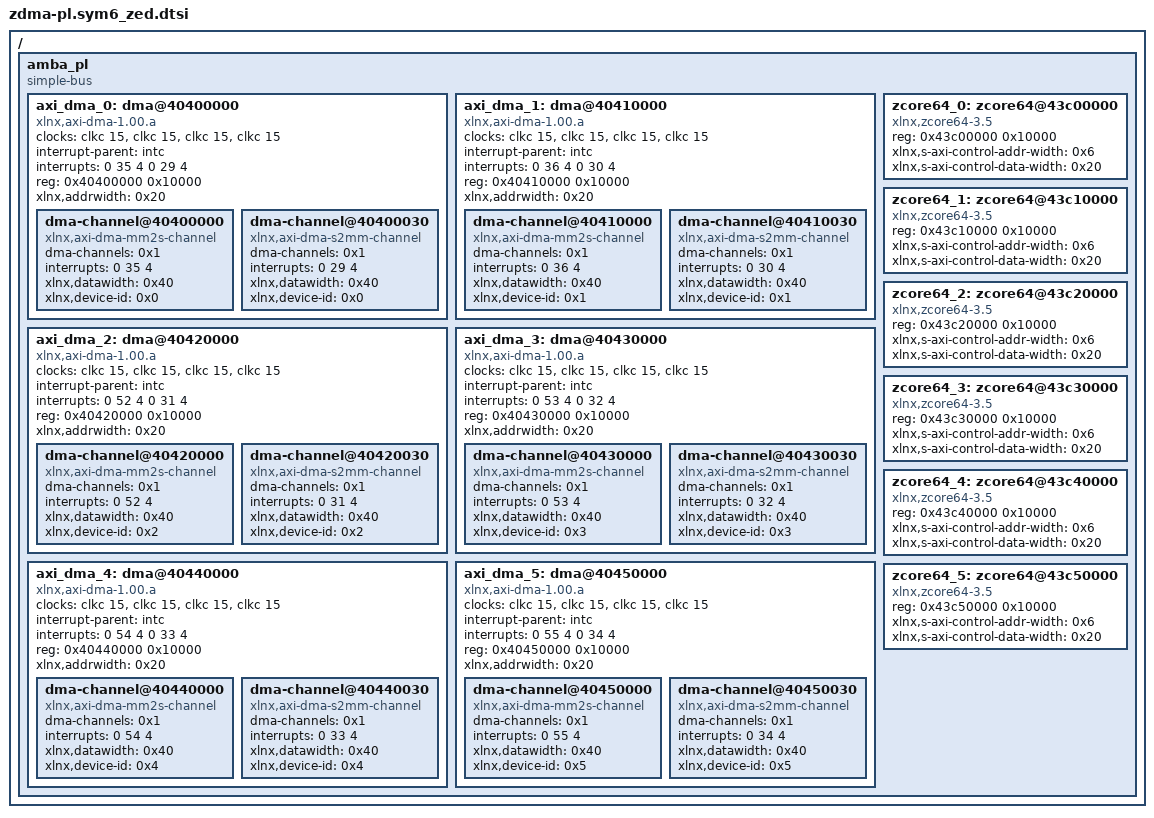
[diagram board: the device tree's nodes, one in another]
/*
 * CAUTION: This file is automatically generated by Xilinx.
 * Version: HSI 2017.2
 * Today is: Tue Jan 16 02:38:08 2018
*/


/ {
	amba_pl: amba_pl {
		#address-cells = <1>;
		#size-cells = <1>;
		compatible = "simple-bus";
		ranges ;
		axi_dma_0: dma@40400000 {
			#dma-cells = <1>;
			clock-names = "s_axi_lite_aclk", "m_axi_sg_aclk", "m_axi_mm2s_aclk", "m_axi_s2mm_aclk";
			clocks = <&clkc 15>, <&clkc 15>, <&clkc 15>, <&clkc 15>;
			compatible = "xlnx,axi-dma-1.00.a";
			interrupt-parent = <&intc>;
			interrupts = <0 35 4 0 29 4>;
			reg = <0x40400000 0x10000>;
			xlnx,addrwidth = <0x20>;
			dma-channel@40400000 {
				compatible = "xlnx,axi-dma-mm2s-channel";
				dma-channels = <0x1>;
				interrupts = <0 35 4>;
				xlnx,datawidth = <0x40>;
				xlnx,device-id = <0x0>;
			};
			dma-channel@40400030 {
				compatible = "xlnx,axi-dma-s2mm-channel";
				dma-channels = <0x1>;
				interrupts = <0 29 4>;
				xlnx,datawidth = <0x40>;
				xlnx,device-id = <0x0>;
			};
		};
		axi_dma_1: dma@40410000 {
			#dma-cells = <1>;
			clock-names = "s_axi_lite_aclk", "m_axi_sg_aclk", "m_axi_mm2s_aclk", "m_axi_s2mm_aclk";
			clocks = <&clkc 15>, <&clkc 15>, <&clkc 15>, <&clkc 15>;
			compatible = "xlnx,axi-dma-1.00.a";
			interrupt-parent = <&intc>;
			interrupts = <0 36 4 0 30 4>;
			reg = <0x40410000 0x10000>;
			xlnx,addrwidth = <0x20>;
			dma-channel@40410000 {
				compatible = "xlnx,axi-dma-mm2s-channel";
				dma-channels = <0x1>;
				interrupts = <0 36 4>;
				xlnx,datawidth = <0x40>;
				xlnx,device-id = <0x1>;
			};
			dma-channel@40410030 {
				compatible = "xlnx,axi-dma-s2mm-channel";
				dma-channels = <0x1>;
				interrupts = <0 30 4>;
				xlnx,datawidth = <0x40>;
				xlnx,device-id = <0x1>;
			};
		};
		axi_dma_2: dma@40420000 {
			#dma-cells = <1>;
			clock-names = "s_axi_lite_aclk", "m_axi_sg_aclk", "m_axi_mm2s_aclk", "m_axi_s2mm_aclk";
			clocks = <&clkc 15>, <&clkc 15>, <&clkc 15>, <&clkc 15>;
			compatible = "xlnx,axi-dma-1.00.a";
			interrupt-parent = <&intc>;
			interrupts = <0 52 4 0 31 4>;
			reg = <0x40420000 0x10000>;
			xlnx,addrwidth = <0x20>;
			dma-channel@40420000 {
				compatible = "xlnx,axi-dma-mm2s-channel";
				dma-channels = <0x1>;
				interrupts = <0 52 4>;
				xlnx,datawidth = <0x40>;
				xlnx,device-id = <0x2>;
			};
			dma-channel@40420030 {
				compatible = "xlnx,axi-dma-s2mm-channel";
				dma-channels = <0x1>;
				interrupts = <0 31 4>;
				xlnx,datawidth = <0x40>;
				xlnx,device-id = <0x2>;
			};
		};
		axi_dma_3: dma@40430000 {
			#dma-cells = <1>;
			clock-names = "s_axi_lite_aclk", "m_axi_sg_aclk", "m_axi_mm2s_aclk", "m_axi_s2mm_aclk";
			clocks = <&clkc 15>, <&clkc 15>, <&clkc 15>, <&clkc 15>;
			compatible = "xlnx,axi-dma-1.00.a";
			interrupt-parent = <&intc>;
			interrupts = <0 53 4 0 32 4>;
			reg = <0x40430000 0x10000>;
			xlnx,addrwidth = <0x20>;
			dma-channel@40430000 {
				compatible = "xlnx,axi-dma-mm2s-channel";
				dma-channels = <0x1>;
				interrupts = <0 53 4>;
				xlnx,datawidth = <0x40>;
				xlnx,device-id = <0x3>;
			};
			dma-channel@40430030 {
				compatible = "xlnx,axi-dma-s2mm-channel";
				dma-channels = <0x1>;
				interrupts = <0 32 4>;
				xlnx,datawidth = <0x40>;
				xlnx,device-id = <0x3>;
			};
		};
		axi_dma_4: dma@40440000 {
			#dma-cells = <1>;
			clock-names = "s_axi_lite_aclk", "m_axi_sg_aclk", "m_axi_mm2s_aclk", "m_axi_s2mm_aclk";
			clocks = <&clkc 15>, <&clkc 15>, <&clkc 15>, <&clkc 15>;
			compatible = "xlnx,axi-dma-1.00.a";
			interrupt-parent = <&intc>;
			interrupts = <0 54 4 0 33 4>;
			reg = <0x40440000 0x10000>;
			xlnx,addrwidth = <0x20>;
			dma-channel@40440000 {
				compatible = "xlnx,axi-dma-mm2s-channel";
				dma-channels = <0x1>;
				interrupts = <0 54 4>;
				xlnx,datawidth = <0x40>;
				xlnx,device-id = <0x4>;
			};
			dma-channel@40440030 {
				compatible = "xlnx,axi-dma-s2mm-channel";
				dma-channels = <0x1>;
				interrupts = <0 33 4>;
				xlnx,datawidth = <0x40>;
				xlnx,device-id = <0x4>;
			};
		};
		axi_dma_5: dma@40450000 {
			#dma-cells = <1>;
			clock-names = "s_axi_lite_aclk", "m_axi_sg_aclk", "m_axi_mm2s_aclk", "m_axi_s2mm_aclk";
			clocks = <&clkc 15>, <&clkc 15>, <&clkc 15>, <&clkc 15>;
			compatible = "xlnx,axi-dma-1.00.a";
			interrupt-parent = <&intc>;
			interrupts = <0 55 4 0 34 4>;
			reg = <0x40450000 0x10000>;
			xlnx,addrwidth = <0x20>;
			dma-channel@40450000 {
				compatible = "xlnx,axi-dma-mm2s-channel";
				dma-channels = <0x1>;
				interrupts = <0 55 4>;
				xlnx,datawidth = <0x40>;
				xlnx,device-id = <0x5>;
			};
			dma-channel@40450030 {
				compatible = "xlnx,axi-dma-s2mm-channel";
				dma-channels = <0x1>;
				interrupts = <0 34 4>;
				xlnx,datawidth = <0x40>;
				xlnx,device-id = <0x5>;
			};
		};
		zcore64_0: zcore64@43c00000 {
			compatible = "xlnx,zcore64-3.5";
			reg = <0x43c00000 0x10000>;
			xlnx,s-axi-control-addr-width = <0x6>;
			xlnx,s-axi-control-data-width = <0x20>;
		};
		zcore64_1: zcore64@43c10000 {
			compatible = "xlnx,zcore64-3.5";
			reg = <0x43c10000 0x10000>;
			xlnx,s-axi-control-addr-width = <0x6>;
			xlnx,s-axi-control-data-width = <0x20>;
		};
		zcore64_2: zcore64@43c20000 {
			compatible = "xlnx,zcore64-3.5";
			reg = <0x43c20000 0x10000>;
			xlnx,s-axi-control-addr-width = <0x6>;
			xlnx,s-axi-control-data-width = <0x20>;
		};
		zcore64_3: zcore64@43c30000 {
			compatible = "xlnx,zcore64-3.5";
			reg = <0x43c30000 0x10000>;
			xlnx,s-axi-control-addr-width = <0x6>;
			xlnx,s-axi-control-data-width = <0x20>;
		};
		zcore64_4: zcore64@43c40000 {
			compatible = "xlnx,zcore64-3.5";
			reg = <0x43c40000 0x10000>;
			xlnx,s-axi-control-addr-width = <0x6>;
			xlnx,s-axi-control-data-width = <0x20>;
		};
		zcore64_5: zcore64@43c50000 {
			compatible = "xlnx,zcore64-3.5";
			reg = <0x43c50000 0x10000>;
			xlnx,s-axi-control-addr-width = <0x6>;
			xlnx,s-axi-control-data-width = <0x20>;
		};
	};
};
